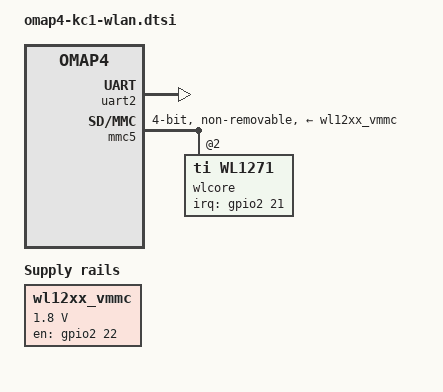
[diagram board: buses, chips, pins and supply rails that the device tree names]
// SPDX-License-Identifier: GPL-2.0-only
/*
 * Maintained by Hansem Ro <hansemro@outlook.com>
 */

/ {
	aliases {
		mmc4 = &mmc5;
	};

	/* regulator for wl12xx on sdio5 */
	wl12xx_vmmc: wl12xx_vmmc {
		pinctrl-names = "default";
		pinctrl-0 = <&wl12xx_gpio>;
		compatible = "regulator-fixed";
		regulator-name = "vwl1271";
		regulator-min-microvolt = <1800000>;
		regulator-max-microvolt = <1800000>;
		gpio = <&gpio2 22 GPIO_ACTIVE_HIGH>; /* gpio_54 */
		startup-delay-us = <70000>;
		enable-active-high;
	};
};

&omap4_pmx_core {
	uart2_pins: pinmux_uart2_pins {
		pinctrl-single,pins = <
			OMAP4_IOPAD(0x118, PIN_INPUT_PULLUP | MUX_MODE0)	/* uart2_cts.uart2_cts */
			OMAP4_IOPAD(0x11a, PIN_OUTPUT | MUX_MODE0)		/* uart2_rts.uart2_rts */
			OMAP4_IOPAD(0x11c, PIN_INPUT_PULLUP | MUX_MODE0)	/* uart2_rx.uart2_rx */
			OMAP4_IOPAD(0x11e, PIN_OUTPUT | MUX_MODE0)		/* uart2_tx.uart2_tx */
		>;
	};

	/* wl12xx GPIO output for WLAN_EN and WLAN_IRQ */
	wl12xx_gpio: pinmux_wl12xx_gpio {
		pinctrl-single,pins = <
			OMAP4_IOPAD(0x07a, PIN_INPUT | MUX_MODE3)		/* gpmc_ncs3.gpio_53 */
			OMAP4_IOPAD(0x07c, PIN_OUTPUT | MUX_MODE3)		/* gpmc_nwp.gpio_54 */
		>;
	};

	/* wl12xx GPIO inputs and SDIO pins */
	wl12xx_pins: pinmux_wl12xx_pins {
		pinctrl-single,pins = <
			OMAP4_IOPAD(0x148, PIN_INPUT_PULLUP | MUX_MODE0)	/* sdmmc5_clk.sdmmc5_clk */
			OMAP4_IOPAD(0x14a, PIN_INPUT_PULLUP | MUX_MODE0)	/* sdmmc5_cmd.sdmmc5_cmd */
			OMAP4_IOPAD(0x14c, PIN_INPUT_PULLUP | MUX_MODE0)	/* sdmmc5_dat0.sdmmc5_dat0 */
			OMAP4_IOPAD(0x14e, PIN_INPUT_PULLUP | MUX_MODE0)	/* sdmmc5_dat1.sdmmc5_dat1 */
			OMAP4_IOPAD(0x150, PIN_INPUT_PULLUP | MUX_MODE0)	/* sdmmc5_dat2.sdmmc5_dat2 */
			OMAP4_IOPAD(0x152, PIN_INPUT_PULLUP | MUX_MODE0)	/* sdmmc5_dat3.sdmmc5_dat3 */
		>;
	};
};

&uart2 {
	pinctrl-names = "default";
	pinctrl-0 = <&uart2_pins>;
	status = "okay";
};

&mmc5 {
	pinctrl-names = "default";
	pinctrl-0 = <&wl12xx_pins>;
	status = "okay";
	vmmc-supply = <&wl12xx_vmmc>;
	non-removable;
	bus-width = <4>;
	cap-power-off-card;

	#address-cells = <1>;
	#size-cells = <0>;
	wlcore: wlcore@2 {
		compatible = "ti,wl1271";
		reg = <2>;
		interrupt-parent = <&gpio2>;
		interrupts = <21 IRQ_TYPE_LEVEL_HIGH>; /* gpio 53 */
		ref-clock-frequency = <26000000>;
		tcxo-clock-frequency = <26000000>;
	};
};
